# ATSAMA5D27WLSOM1 device description
Architecture: CORTEX-A5; Family: SAMA5; Series: SAMA5D2
Registers are 32-bit, read-write, no defined reset value unless marked. A register's access mark holds for its fields unless they carry their own. Offsets are from the block's base; [hi:lo] are bit positions; {n}, {i} and the like mark numbered series; 'fields as' and 'values as' point back to an identical list; <NAME> marks a mode.

## SPI — Serial Peripheral Interface
Instances: SPI0 0xF8000000, SPI1 0xFC000000
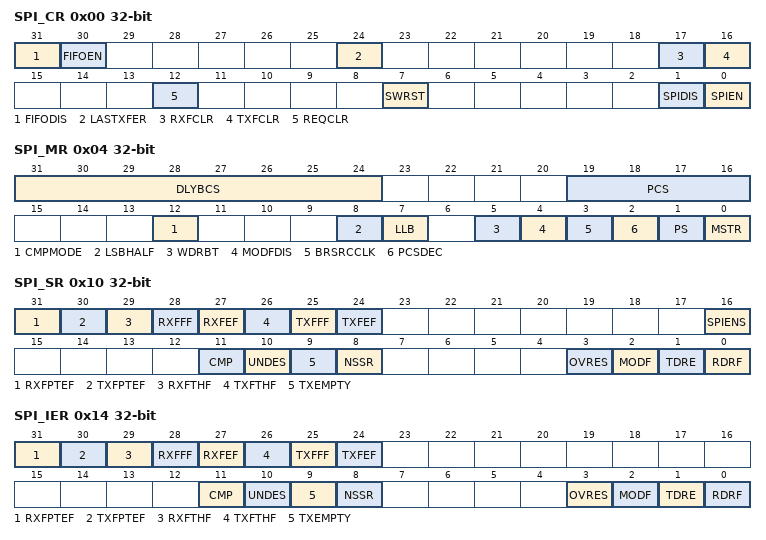
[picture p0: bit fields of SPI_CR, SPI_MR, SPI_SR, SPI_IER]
0x00 SPI_CR wo — Control Register
  [31] FIFODIS — FIFO Disable
  [30] FIFOEN — FIFO Enable
  [24] LASTXFER — Last Transfer
  [17] RXFCLR — Receive FIFO Clear
  [16] TXFCLR — Transmit FIFO Clear
  [12] REQCLR — Request to Clear the Comparison Trigger
  [7] SWRST — SPI Software Reset
  [1] SPIDIS — SPI Disable
  [0] SPIEN — SPI Enable
0x04 SPI_MR — Mode Register
  [31:24] DLYBCS — Delay Between Chip Selects
  [19:16] PCS — Peripheral Chip Select
    14=NPCS0 (NPCS0 as Chip Select); 13=NPCS1 (NPCS1 as Chip Select); 11=NPCS2 (NPCS2 as Chip Select); 7=NPCS3 (NPCS3 as Chip Select)
  [12] CMPMODE — Comparison Mode
    0=FLAG_ONLY (Any character is received and comparison function drives CMP flag.); 1=START_CONDITION (Comparison condition must be met to start reception of all incoming characters until REQCLR is set.)
  [8] LSBHALF — LSB Timing Selection
  [7] LLB — Local Loopback Enable
  [5] WDRBT — Wait Data Read Before Transfer
  [4] MODFDIS — Mode Fault Detection
  [3] BRSRCCLK — Bit Rate Source Clock
    0=PERIPH_CLK (The peripheral clock is the source clock for the bit rate generation.); 1=GCLK (PMC GCLK is the source clock for the bit rate generation, thus the bit rate can be independent of the core/peripheral clock.)
  [2] PCSDEC — Chip Select Decode
  [1] PS — Peripheral Select
  [0] MSTR — Master/Slave Mode
    1=MASTER; 0=SLAVE
0x08 SPI_RDR ro (modes: DEFAULT when SPI_FIFO_ONE_DATA_RX.SPI_FMR.RXRDYM=0x0; FIFO_MULTI_DATA_8 when SPI_FIFO_TWO_DATA_RX.SPI_FMR.RXRDYM=0x1; FIFO_MULTI_DATA_16 when SPI_FIFO_FOUR_DATA_RX.SPI_FMR.RXRDYM=0x2) — Receive Data Register
  [19:16] PCS <DEFAULT> — Peripheral Chip Select
  [15:0] RD <DEFAULT> — Receive Data
  [31:16] RD1 <FIFO_MULTI_DATA_16> — Receive Data
  [15:0] RD0 <FIFO_MULTI_DATA_16> — Receive Data
  [31:24] RD3 <FIFO_MULTI_DATA_8> — Receive Data
  [23:16] RD2 <FIFO_MULTI_DATA_8> — Receive Data
  [15:8] RD1 <FIFO_MULTI_DATA_8> — Receive Data
  [7:0] RD0 <FIFO_MULTI_DATA_8> — Receive Data
0x0C SPI_TDR wo — Transmit Data Register
  [24] LASTXFER <DEFAULT> — Last Transfer
  [19:16] PCS <DEFAULT> — Peripheral Chip Select
    values as SPI_MR.PCS
  [15:0] TD <DEFAULT> — Transmit Data
  [31:16] TD1 <FIFO_MULTI_DATA> — Transmit Data
  [15:0] TD0 <FIFO_MULTI_DATA> — Transmit Data
0x10 SPI_SR ro — Status Register
  [31] RXFPTEF — Receive FIFO Pointer Error Flag
  [30] TXFPTEF — Transmit FIFO Pointer Error Flag
  [29] RXFTHF — Receive FIFO Threshold Flag
  [28] RXFFF — Receive FIFO Full Flag
  [27] RXFEF — Receive FIFO Empty Flag
  [26] TXFTHF — Transmit FIFO Threshold Flag (cleared on read)
  [25] TXFFF — Transmit FIFO Full Flag (cleared on read)
  [24] TXFEF — Transmit FIFO Empty Flag (cleared on read)
  [16] SPIENS — SPI Enable Status
  [11] CMP — Comparison Status (cleared on read)
  [10] UNDES — Underrun Error Status (Slave mode only) (cleared on read)
  [9] TXEMPTY — Transmission Registers Empty (cleared by writing SPI_TDR)
  [8] NSSR — NSS Rising (cleared on read)
  [3] OVRES — Overrun Error Status (cleared on read)
  [2] MODF — Mode Fault Error (cleared on read)
  [1] TDRE — Transmit Data Register Empty (cleared by writing SPI_TDR)
  [0] RDRF — Receive Data Register Full (cleared by reading SPI_RDR)
0x14 SPI_IER wo (atomic set of SPI_IMR) — Interrupt Enable Register
  [31] RXFPTEF — RXFPTEF Interrupt Enable
  [30] TXFPTEF — TXFPTEF Interrupt Enable
  [29] RXFTHF — RXFTHF Interrupt Enable
  [28] RXFFF — RXFFF Interrupt Enable
  [27] RXFEF — RXFEF Interrupt Enable
  [26] TXFTHF — TXFTHF Interrupt Enable
  [25] TXFFF — TXFFF Interrupt Enable
  [24] TXFEF — TXFEF Interrupt Enable
  [11] CMP — Comparison Interrupt Enable
  [10] UNDES — Underrun Error Interrupt Enable
  [9] TXEMPTY — Transmission Registers Empty Enable
  [8] NSSR — NSS Rising Interrupt Enable
  [3] OVRES — Overrun Error Interrupt Enable
  [2] MODF — Mode Fault Error Interrupt Enable
  [1] TDRE — SPI Transmit Data Register Empty Interrupt Enable
  [0] RDRF — Receive Data Register Full Interrupt Enable
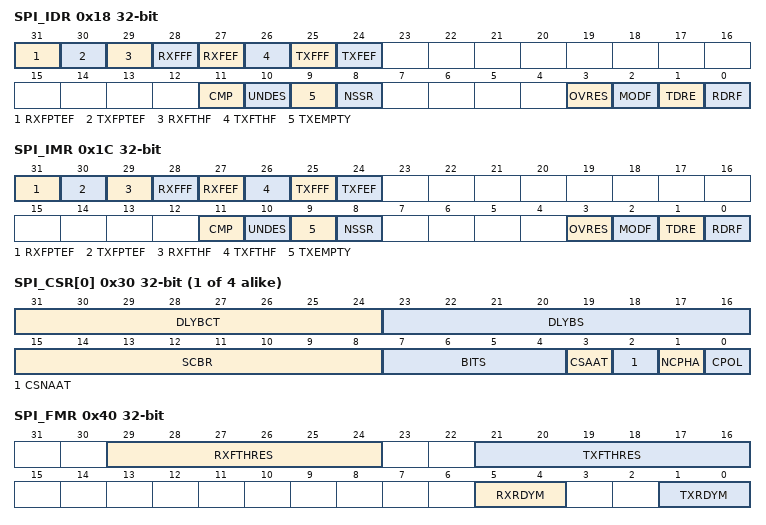
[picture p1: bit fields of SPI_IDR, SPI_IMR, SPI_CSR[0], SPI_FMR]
0x18 SPI_IDR wo (atomic clear of SPI_IMR) — Interrupt Disable Register
  [31] RXFPTEF — RXFPTEF Interrupt Disable
  [30] TXFPTEF — TXFPTEF Interrupt Disable
  [29] RXFTHF — RXFTHF Interrupt Disable
  [28] RXFFF — RXFFF Interrupt Disable
  [27] RXFEF — RXFEF Interrupt Disable
  [26] TXFTHF — TXFTHF Interrupt Disable
  [25] TXFFF — TXFFF Interrupt Disable
  [24] TXFEF — TXFEF Interrupt Disable
  [11] CMP — Comparison Interrupt Disable
  [10] UNDES — Underrun Error Interrupt Disable
  [9] TXEMPTY — Transmission Registers Empty Disable
  [8] NSSR — NSS Rising Interrupt Disable
  [3] OVRES — Overrun Error Interrupt Disable
  [2] MODF — Mode Fault Error Interrupt Disable
  [1] TDRE — SPI Transmit Data Register Empty Interrupt Disable
  [0] RDRF — Receive Data Register Full Interrupt Disable
0x1C SPI_IMR ro (atomic read) — Interrupt Mask Register
  [31] RXFPTEF — RXFPTEF Interrupt Mask
  [30] TXFPTEF — TXFPTEF Interrupt Mask
  [29] RXFTHF — RXFTHF Interrupt Mask
  [28] RXFFF — RXFFF Interrupt Mask
  [27] RXFEF — RXFEF Interrupt Mask
  [26] TXFTHF — TXFTHF Interrupt Mask
  [25] TXFFF — TXFFF Interrupt Mask
  [24] TXFEF — TXFEF Interrupt Mask
  [11] CMP — Comparison Interrupt Mask
  [10] UNDES — Underrun Error Interrupt Mask
  [9] TXEMPTY — Transmission Registers Empty Mask
  [8] NSSR — NSS Rising Interrupt Mask
  [3] OVRES — Overrun Error Interrupt Mask
  [2] MODF — Mode Fault Error Interrupt Mask
  [1] TDRE — SPI Transmit Data Register Empty Interrupt Mask
  [0] RDRF — Receive Data Register Full Interrupt Mask
{0x30+4i} SPI_CSR[{i}] (i=0..3) — Chip Select Register
  [31:24] DLYBCT — Delay Between Consecutive Transfers
  [23:16] DLYBS — Delay Before SPCK
  [15:8] SCBR — Serial Clock Bit Rate
  [7:4] BITS — Bits Per Transfer
    {v}=_{v+8}_BIT ({v+8} bits for transfer) (v=0..8)
  [3] CSAAT — Chip Select Active After Transfer
  [2] CSNAAT — Chip Select Not Active After Transfer (ignored if CSAAT = 1)
  [1] NCPHA — Clock Phase
    1=VALID_LEADING_EDGE (Data is valid on clock leading edge (NCPHA=1)); 0=VALID_TRAILING_EDGE (Data is valid on clock trailing edge (NCPHA=0))
  [0] CPOL — Clock Polarity
    0=IDLE_LOW (Clock is low when inactive (CPOL=0)); 1=IDLE_HIGH (Clock is high when inactive (CPOL=1))
0x40 SPI_FMR — FIFO Mode Register
  [29:24] RXFTHRES — Receive FIFO Threshold
  [21:16] TXFTHRES — Transmit FIFO Threshold
  [5:4] RXRDYM — Receive Data Register Full Mode
    0=ONE_DATA (RDRF will be at level '1' when at least one unread data is in the Receive FIFO.); 1=TWO_DATA (RDRF will be at level '1' when at least two unread data are in the Receive FIFO. Cannot be used if SPI_MR.PS =1.); 2=FOUR_DATA (RDRF will be at level '1' when at least four unread data are in the Receive FIFO. Cannot be used when SPI_CSRx.BITS is greater than 0, or if SPI_MR.MSTR =1, or if SPI_MR.PS =1.)
  [1:0] TXRDYM — Transmit Data Register Empty Mode
    0=ONE_DATA (TDRE will be at level '1' when at least one data can be written in the Transmit FIFO.); 1=TWO_DATA (TDRE will be at level '1' when at least two data can be written in the Transmit FIFO. Cannot be used if SPI_MR.PS =1.)
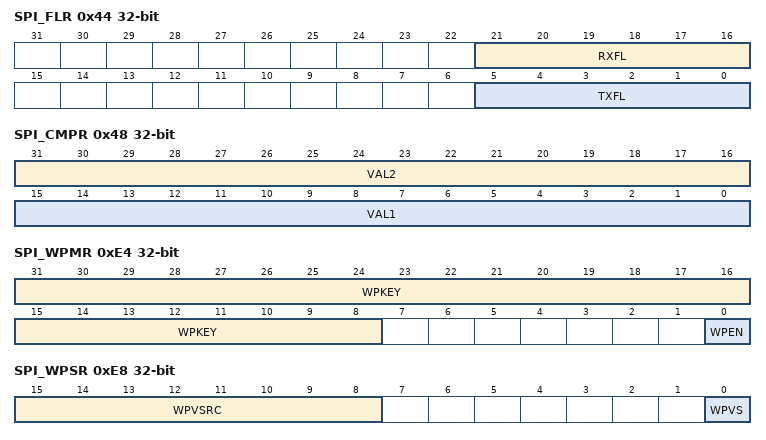
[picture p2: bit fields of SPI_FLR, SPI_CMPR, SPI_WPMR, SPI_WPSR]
0x44 SPI_FLR ro — FIFO Level Register
  [21:16] RXFL — Receive FIFO Level
  [5:0] TXFL — Transmit FIFO Level
0x48 SPI_CMPR ro — Comparison Register
  [31:16] VAL2 — Second Comparison Value for Received Character
  [15:0] VAL1 — First Comparison Value for Received Character
0xE4 SPI_WPMR — Write Protection Mode Register
  [31:8] WPKEY — Write Protection Key
    0x535049=PASSWD (Writing any other value in this field aborts the write operation of the WPEN bit.Always reads as 0.)
  [0] WPEN — Write Protection Enable
0xE8 SPI_WPSR ro — Write Protection Status Register
  [15:8] WPVSRC — Write Protection Violation Source
  [0] WPVS — Write Protection Violation Status
